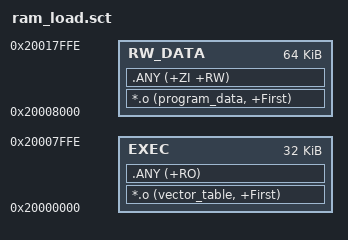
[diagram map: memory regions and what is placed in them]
LOAD_REGION1 0x20000000 0x00008000  { ;code + RO data
  EXEC 0x20000000 0x00007FFF{
   *.o (vector_table, +First)
   .ANY (+RO)
  }
}

LOAD_REGION2 0x20008000 0x0000FFFF  { ; RW data
  RW_DATA 0x20008000 0x0000FFFF{
   *.o (program_data, +First)
   .ANY (+ZI +RW)
  }
}

